# STM32WB30CEU6A register map
File version: 1.0
Registers are 32-bit, access not given, reset 0x0 unless marked. A register's access mark holds for its fields unless they carry their own. Offsets are from the block's base; [hi:lo] are bit positions; {n}, {i} and the like mark numbered series.

## GPIOC
Base 0x48000800
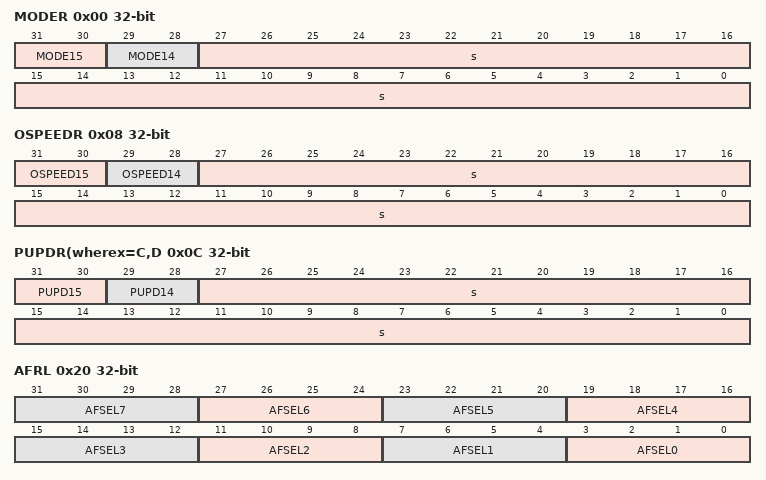
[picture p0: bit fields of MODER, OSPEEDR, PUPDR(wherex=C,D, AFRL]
0x00 MODER
  [31:30] MODE15, [29:28] MODE14, [27:0] s
0x04 OTYPER
  [15] OT15, [14] OT14, [31:0] s
0x08 OSPEEDR
  [31:30] OSPEED15, [29:28] OSPEED14, [27:0] s
0x0C PUPDR(wherex=C,D
  [31:30] PUPD15, [29:28] PUPD14, [27:0] s
0x10 IDR
  [15] ID15, [14] ID14, [31:0] s
0x14 ODR
  [15] OD15, [14] OD14, [31:0] s
0x18 BSRR
  [31] BR15, [30] BR14, [15] BS15, [14] BS14, [29:0] s
0x1C LCKR
  [16] LCKK, [15] LCK15, [14] LCK14, [31:0] s
0x20 AFRL
  [4n+3:4n] AFSEL{n} (n=0..7)
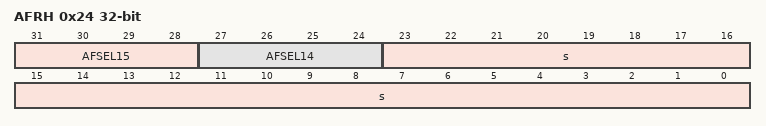
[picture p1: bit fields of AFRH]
0x24 AFRH
  [31:28] AFSEL15, [27:24] AFSEL14, [23:0] s
0x28 BRR
  [15] BR15, [14] BR14, [31:0] s

## GPIOE
Base 0x48001000
0x00 MODER
  [9:8] MODE4, [31:0] s
0x04 OTYPER
  [4] OT4, [31:0] s
0x08 OSPEEDR
  [9:8] OSPEED4, [31:0] s
0x0C PUPDR
  [9:8] PUPD4, [31:0] s
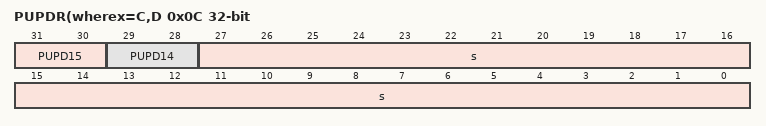
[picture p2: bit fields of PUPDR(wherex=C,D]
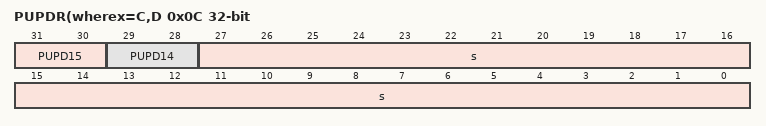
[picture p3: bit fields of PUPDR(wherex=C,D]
0x0C PUPDR(wherex=C,D
  [31:30] PUPD15, [29:28] PUPD14, [27:0] s
0x10 IDR
  [4] ID4, [31:0] s
0x14 ODR
  [4] OD4, [31:0] s
0x18 BSRR
  [20] BR4, [4] BS4, [31:0] s
0x1C LCKR
  [16] LCKK, [4] LCK4, [31:0] s
0x20 AFRL
  [19:16] AFSEL4, [31:0] s
0x28 BRR
  [4] BR4, [31:0] s

## GPIOH
Base 0x48001C00
0x00 MODER
  [7:6] MODE3, [31:0] s
0x04 OTYPER
  [3] OT3, [31:0] s
0x08 OSPEEDR
  [7:6] OSPEED3, [31:0] s
0x0C PUPDR
  [7:6] PUPD3, [31:0] s
0x0C PUPDR(wherex=C,D
  [31:30] PUPD15, [29:28] PUPD14, [27:0] s
0x10 IDR
  [3] ID3, [31:0] s
0x14 ODR
  [3] OD3, [31:0] s
0x18 BSRR
  [19] BR3, [3] BS3, [31:0] s
0x1C LCKR
  [16] LCKK, [3] LCK3, [31:0] s
0x20 AFRL
  [15:12] AFSEL3, [31:0] s
0x28 BRR
  [3] BR3, [31:0] s

## ADC
Base 0x50040000
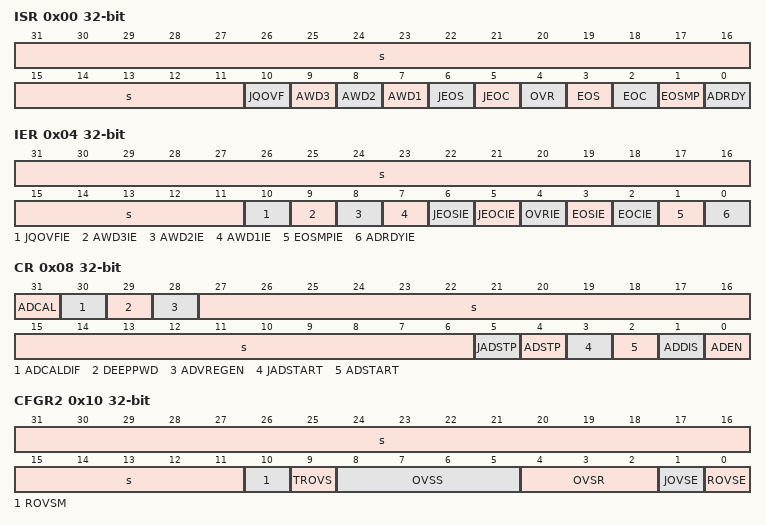
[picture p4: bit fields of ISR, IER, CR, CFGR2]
0x00 ISR
  [31:11] s, [10] JQOVF, [9] AWD3, [8] AWD2, [7] AWD1, [6] JEOS, [5] JEOC, [4] OVR, [3] EOS, [2] EOC, [1] EOSMP, [0] ADRDY
0x04 IER
  [31:11] s, [10] JQOVFIE, [9] AWD3IE, [8] AWD2IE, [7] AWD1IE, [6] JEOSIE, [5] JEOCIE, [4] OVRIE, [3] EOSIE, [2] EOCIE, [1] EOSMPIE, [0] ADRDYIE
0x08 CR
  [31] ADCAL, [30] ADCALDIF, [29] DEEPPWD, [28] ADVREGEN, [27:6] s, [5] JADSTP, [4] ADSTP, [3] JADSTART, [2] ADSTART, [1] ADDIS, [0] ADEN
0x0C CFGR
  [31] JQDIS, [30:26] AWD1CH, [25] JAUTO, [24] JAWD1EN, [23] AWD1EN, [22] AWD1SGL, [21] JQM, [20] JDISCEN, [19:17] DISCNUM, [16] DISCEN, [14] AUTDLY, [13] CONT, [12] OVRMOD, [11:10] EXTEN, [n+6] EXTSEL{n} (n=0..3), [5] ALIGN, [4:3] RES, [15:2] s, [1] DMACFG, [0] DMAEN
0x10 CFGR2
  [31:11] s, [10] ROVSM, [9] TROVS, [8:5] OVSS, [4:2] OVSR, [1] JOVSE, [0] ROVSE
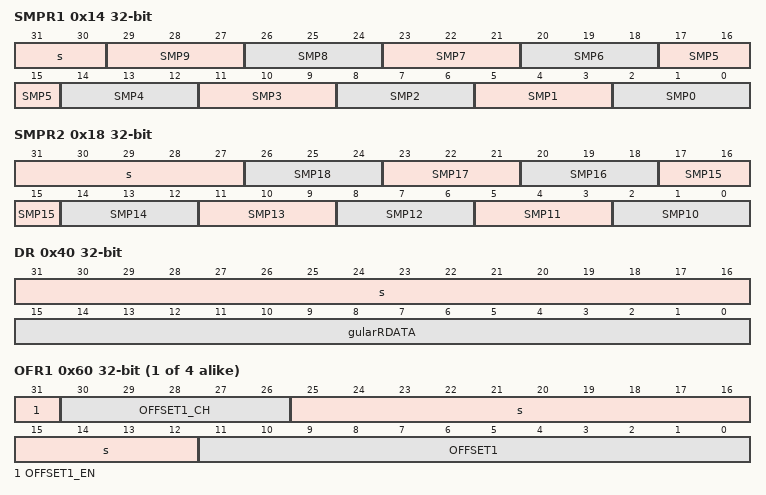
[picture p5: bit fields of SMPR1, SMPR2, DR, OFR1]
0x14 SMPR1
  [31:30] s, [3n+2:3n] SMP{n} (n=0..9)
0x18 SMPR2
  [31:27] s, [3n-28:3n-30] SMP{n} (n=10..18)
0x20 TR1
  [27:16] HT1, [31:12] s, [11:0] LT1
0x24 TR2
  [23:16] HT2, [31:8] s, [7:0] LT2
0x28 TR3
  [23:16] HT3, [31:8] s, [7:0] LT3
0x30 SQR1
  [6n+4:6n] SQ{n} (n=1..4), [31:4] s, [3:0] L
0x34 SQR2
  [6n-26:6n-30] SQ{n} (n=5..9), [31:5] s
0x38 SQR3
  [6n-56:6n-60] SQ{n} (n=10..14), [31:5] s
0x3C SQR4
  [10:6] SQ16, [31:5] s, [4:0] SQ15
0x40 DR
  [31:16] s, [15:0] gularRDATA
0x4C JSQR
  [6n+6:6n+2] JSQ{n} (n=1..4), [31:13] s, [7:6] JEXTEN, [5:2] JEXTSEL, [1:0] JL
{0x5C+4i} OFR{i} (i=1..4)
  [31] OFFSET{i}_EN, [30:26] OFFSET{i}_CH, [25:12] s, [11:0] OFFSET{i}
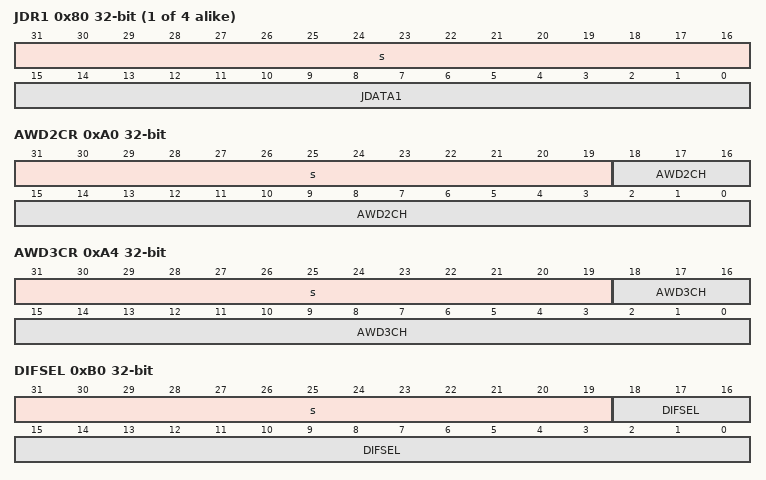
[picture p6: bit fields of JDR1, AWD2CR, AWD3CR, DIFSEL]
{0x7C+4i} JDR{i} (i=1..4)
  [31:16] s, [15:0] JDATA{i}
0xA0 AWD2CR
  [31:19] s, [18:0] AWD2CH
0xA4 AWD3CR
  [31:19] s, [18:0] AWD3CH
0xB0 DIFSEL
  [31:19] s, [18:0] DIFSEL
0xB4 CALFACT
  [22:16] CALFACT_D, [31:7] s, [6:0] CALFACT_S

## PWR
Base 0x58000400
0x00 CR1
  [14] LPR, [8] DBP, [5] FPDS, [4] FPDR, [31:3] s, [2:0] LPMS
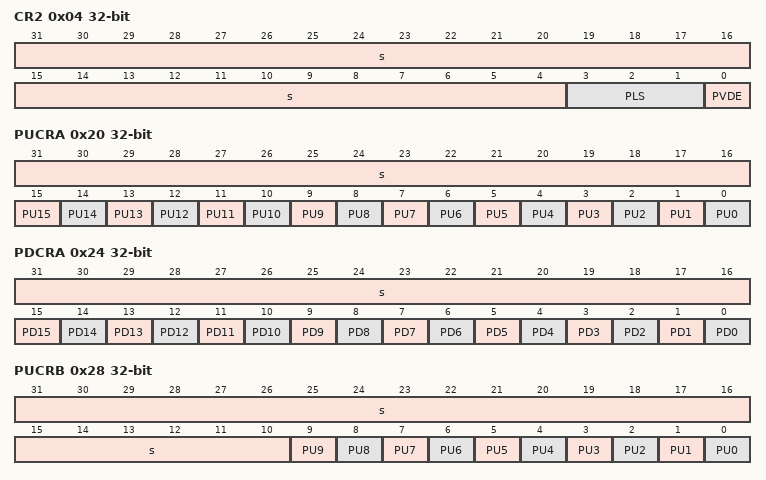
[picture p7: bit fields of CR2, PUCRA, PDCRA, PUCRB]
0x04 CR2
  [31:4] s, [3:1] PLS, [0] PVDE
0x08 CR3
  [15] EIWUL, [14] EC2H, [13] E802A, [12] EBLEA, [11] ECRPE, [10] APC, [9] RRS, [3] EWUP4, [31:1] s, [0] EWUP1
0x0C CR4
  [15] C2BOOT, [9] VBRS, [8] VBE, [3] WP4, [31:1] s, [0] WP1
0x10 SR1
  [15] WUFI, [14] C2HF, [13] 802AF, [12] BLEAF, [11] CRPEF, [10] 802WUF, [9] BLEWUF, [8] BORHF, [3] WUF4, [31:1] s, [0] WUF1
0x14 SR2
  [11] PVDO, [9] REGLPF, [8] REGLPS, [31:0] s
0x18 SCR
  [14] CC2HF, [13] C802AF, [12] CBLEAF, [11] CCRPEF, [10] C802WUF, [9] CBLEWUF, [8] CBORHF, [3] CWUF4, [31:1] s, [0] CWUF1
0x20 PUCRA
  [31:16] s, [n] PU{n} (n=0..15)
0x24 PDCRA
  [31:16] s, [n] PD{n} (n=0..15)
0x28 PUCRB
  [31:10] s, [n] PU{n} (n=0..9)
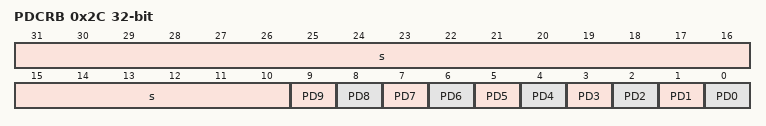
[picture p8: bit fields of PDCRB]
0x2C PDCRB
  [31:10] s, [n] PD{n} (n=0..9)
0x30 PUCRC
  [15] PU15, [14] PU14, [31:0] s
0x34 PDCRC
  [15] PD15, [14] PD14, [31:0] s
0x40 PUCRE
  [4] PU4, [31:0] s
0x44 PDCRE
  [4] PD4, [31:0] s
0x58 PUCRH
  [3] PU3, [31:0] s
0x5C PDCRH
  [3] PD3, [31:0] s
0x80 C2CR1
  [15] 802WKUP, [14] BLEEWKUP, [5] FPDS, [4] FPDR, [31:3] s, [2:0] LPMS
0x84 C2CR3
  [15] EIWUL, [12] APC, [10] E802IWUP, [9] EBLEWUP, [3] EWUP4, [31:1] s, [0] EWUP1
0x88 EXTSCR
  [15] C2DS, [14] C1DS, [13] CRPF, [11] C2STOPF, [10] C2SBF, [9] C1STOPF, [8] C1SBF, [31:3] s, [2] CCRPF, [1] C2CSSF, [0] C1CSSF

## EXTI
Base 0x58000800
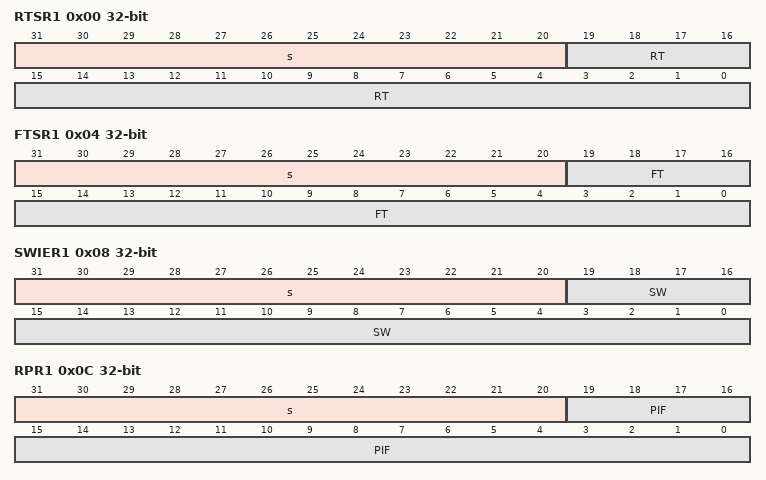
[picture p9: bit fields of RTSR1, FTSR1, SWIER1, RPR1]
0x00 RTSR1
  [31:20] s, [19:0] RT
0x04 FTSR1
  [31:20] s, [19:0] FT
0x08 SWIER1
  [31:20] s, [19:0] SW
0x0C RPR1
  [31:20] s, [19:0] PIF
0x20 RTSR2
  [9:8] RT, [1] RT33, [31:0] s
0x24 FTSR2
  [9:8] FT, [1] FT33, [31:0] s
0x28 SWIER2
  [9:8] SWI, [1] SWI33, [31:0] s
0x2C PR2
  [9:8] PIF, [1] PIF33, [31:0] s
0x80 IMR1
  [24] IM24, [22] IM22, [31:20] s, [30:0] IM
0x84 EMR1
  [31:16] s, [19:0] EM
0x90 IMR2
  [16:1] IM, [31:0] s
0x94 EMR2
  [9:8] EM, [31:0] s
0xC0 C2IMR1
  [24] IM24, [22] IM22, [31:20] s, [30:0] IM
0xC4 C2EMR1
  [31:16] s, [19:0] EM
0xD0 CIMR2
  [16] IM48, [14:4] IM, [1] IM33, [31:0] s
0xD4 C2EMR2
  [9:8] EM, [31:0] s

## IPCC
Base 0x58000C00
0x00 C1CR
  [16] TXFIE, [31:1] s, [0] RXOIE
0x04 C1MR
  [n+15] CH{n}FM (n=1..6), [31:6] s, [n-1] CH{n}OM (n=1..6)
0x08 C1SCR
  [n+15] CH{n}S (n=1..6), [31:6] s, [n-1] CH{n}C (n=1..6)
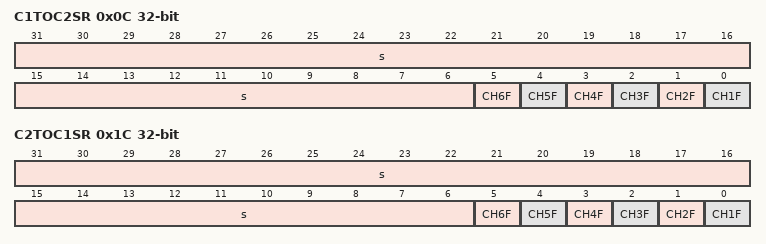
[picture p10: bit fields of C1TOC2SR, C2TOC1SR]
0x0C C1TOC2SR
  [31:6] s, [n-1] CH{n}F (n=1..6)
0x10 C2CR
  [16] TXFIE, [31:1] s, [0] RXOIE
0x14 C2MR
  [n+15] CH{n}FM (n=1..6), [31:6] s, [n-1] CH{n}OM (n=1..6)
0x18 C2SCR
  [n+15] CH{n}S (n=1..6), [31:6] s, [n-1] CH{n}C (n=1..6)
0x1C C2TOC1SR
  [31:6] s, [n-1] CH{n}F (n=1..6)

## TRNG
Base 0x58001000
0x00 CR
  [5] CED, [3] IE, [2] RNGEN, [31:0] s
0x04 SR
  [6] SEIS, [5] CEIS, [31:3] s, [2] SECS, [1] CECS, [0] DRDY
0x08 DR
  [31:0] RNDATA

## HSEM
Base 0x58001400
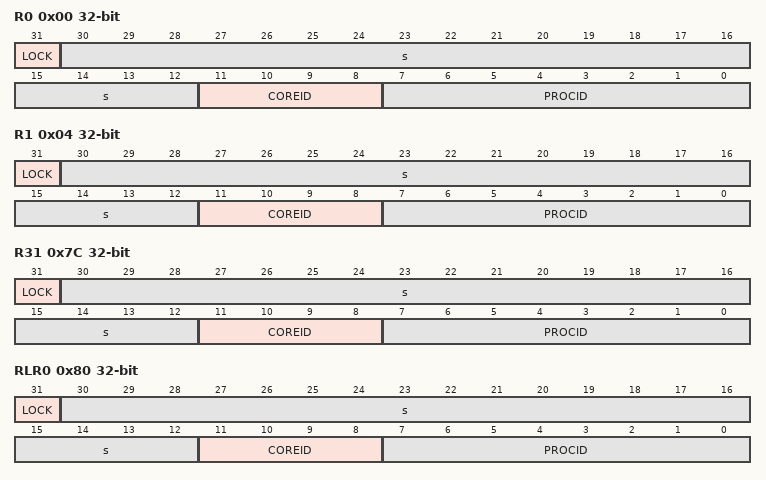
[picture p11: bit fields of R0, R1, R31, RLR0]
0x00 R0
  [31] LOCK, [30:12] s, [11:8] COREID, [7:0] PROCID
0x04 R1
  [31] LOCK, [30:12] s, [11:8] COREID, [7:0] PROCID
0x7C R31
  [31] LOCK, [30:12] s, [11:8] COREID, [7:0] PROCID
0x80 RLR0
  [31] LOCK, [30:12] s, [11:8] COREID, [7:0] PROCID
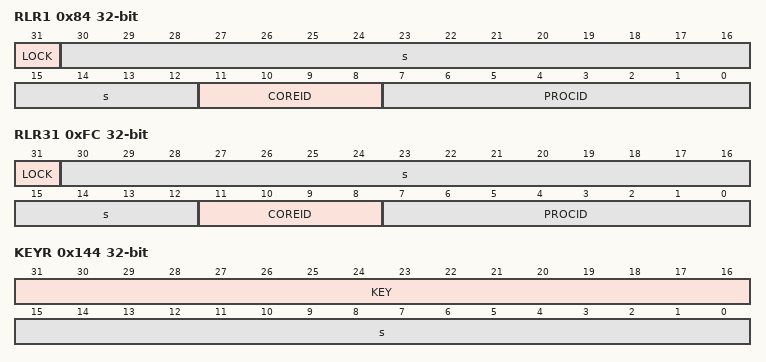
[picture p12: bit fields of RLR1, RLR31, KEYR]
0x84 RLR1
  [31] LOCK, [30:12] s, [11:8] COREID, [7:0] PROCID
0xFC RLR31
  [31] LOCK, [30:12] s, [11:8] COREID, [7:0] PROCID
0x100 C1IER
  [31:0] ISE
0x104 C1ICR
  [31:0] ISC
0x108 C1ISR
  [31:0] ISF
0x10C C1MISR
  [31:0] MISF
0x110 C2IER
  [31:0] ISE
0x114 C2ICR
  [31:0] ISC
0x118 C2ISR
  [31:0] ISF
0x11C C2MISR
  [31:0] MISF
0x140 CR
  [31:16] KEY, [11:8] COREID, [15:0] s
0x144 KEYR
  [31:16] KEY, [15:0] s

## AES2
Base 0x58001800
0x00 CR
  [23:20] NPBLB, [18] KEYSIZE, [31:15] s, [14:13] GCMPH, [12] DMAOUTEN, [11] DMAINEN, [10] ERRIE, [9] CCFIE, [8] ERRC, [7] CCFC, [16:5] CHMOD, [4:3] MODE, [2:1] DATATYPE, [0] EN
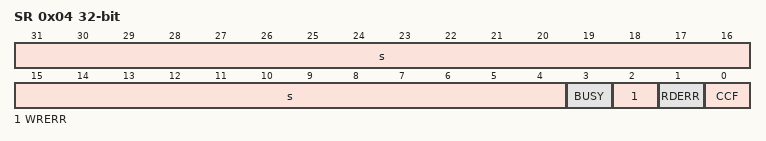
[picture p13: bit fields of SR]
0x04 SR
  [31:4] s, [3] BUSY, [2] WRERR, [1] RDERR, [0] CCF
0x08 DINR
  [31:0] DIN
0x0C DOUTR
  [31:0] DOUT
{0x10+4i} KEYR{i} (i=0..3)
  [31:0] KEY
{0x20+4i} IVR{i} (i=0..3)
  [31:0] IVI
{0x20+4i} KEYR{i} (i=4..7)
  [31:0] KEY
{0x40+4i} SUSP{i}R (i=0..7)
  [31:0] SUSP

## PKA
Base 0x58002000
Same registers: PKARAM 0x58002400
0x00 CR
  [20] ADDRERRIE, [19] RAMERRIE, [17] PROCENDIE, [13:8] MODE, [31:2] s, [1] START, [0] EN
0x04 SR
  [20] ADDRERRF, [19] RAMERRF, [17] PROCENDF, [16] BUSY, [31:0] s
0x08 CLRFR
  [20] ADDRERRFC, [19] RAMERRFC, [17] PROCENDFC, [31:0] s
